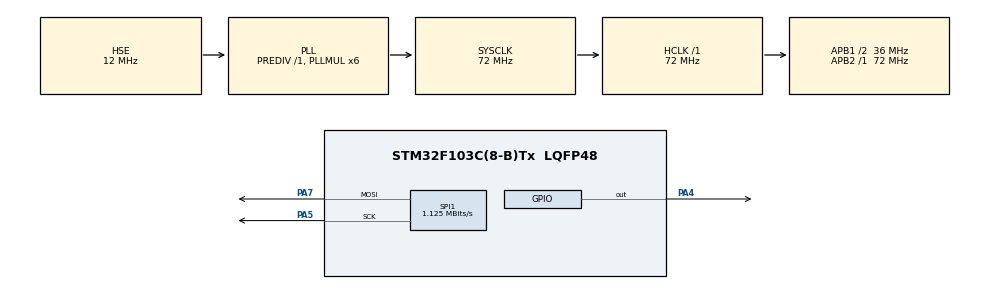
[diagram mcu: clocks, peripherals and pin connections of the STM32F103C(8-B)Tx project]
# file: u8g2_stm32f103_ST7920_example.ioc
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Mcu.Family=STM32F1
RCC.PLLSourceVirtual=RCC_PLLSOURCE_HSE
PA7.Mode=TX_Only_Simplex_Unidirect_Master
PD1-OSC_OUT.Mode=HSE-External-Oscillator
SPI1.VirtualType=VM_MASTER
PD0-OSC_IN.Signal=RCC_OSC_IN
RCC.APB1CLKDivider=RCC_HCLK_DIV2
RCC.SYSCLKSource=RCC_SYSCLKSOURCE_PLLCLK
ProjectManager.StackSize=0x400
PD1-OSC_OUT.Signal=RCC_OSC_OUT
PA13.Signal=SYS_JTMS-SWDIO
ProjectManager.TargetToolchain=STM32CubeIDE
SPI1.Direction=SPI_DIRECTION_2LINES
RCC.HCLKFreq_Value=72000000
RCC.APB2TimFreq_Value=72000000
SPI1.CalculateBaudRate=1.125 MBits/s
RCC.USBFreq_Value=72000000
RCC.AHBFreq_Value=72000000
PD0-OSC_IN.Mode=HSE-External-Oscillator
PA5.Signal=SPI1_SCK
RCC.HSE_VALUE=12000000
board=custom
RCC.PLLMUL=RCC_PLL_MUL6
RCC.APB2Freq_Value=72000000
SPI1.Mode=SPI_MODE_MASTER
PA14.Mode=Serial_Wire
PA13.Mode=Serial_Wire
Mcu.Name=STM32F103C(8-B)Tx
PA4.Signal=GPIO_Output
RCC.SYSCLKFreq_VALUE=72000000
Mcu.Package=LQFP48
PA14.Signal=SYS_JTCK-SWCLK
ProjectManager.HeapSize=0x200
NVIC.PriorityGroup=NVIC_PRIORITYGROUP_4
RCC.APB1TimFreq_Value=72000000
RCC.APB1Freq_Value=36000000
SPI1.BaudRatePrescaler=SPI_BAUDRATEPRESCALER_64
PA5.Mode=TX_Only_Simplex_Unidirect_Master
PA7.Signal=SPI1_MOSI

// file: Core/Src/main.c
/* USER CODE BEGIN Header */
/**
  ******************************************************************************
  * @file           : main.c
  * @brief          : Main program body
  ******************************************************************************
  * @attention
  *
  * <h2><center>&copy; Copyright (c) 2021 STMicroelectronics.
  * All rights reserved.</center></h2>
  *
  * This software component is licensed by ST under BSD 3-Clause license,
  * the "License"; You may not use this file except in compliance with the
  * License. You may obtain a copy of the License at:
  *                        opensource.org/licenses/BSD-3-Clause
  *
  ******************************************************************************
  */
/* USER CODE END Header */
#include "main.h"

/* USER CODE BEGIN Includes */
#include "u8g2.h"
#include "../u8g2/u8g2.h"
/* USER CODE END Includes */

SPI_HandleTypeDef hspi1;

/* USER CODE BEGIN PV */
static u8g2_t u8g2;
/* USER CODE END PV */

void SystemClock_Config(void);
static void MX_GPIO_Init(void);
static void MX_SPI1_Init(void);
/* USER CODE BEGIN PFP */

/* Private variables ---------------------------------------------------------*/

/* USER CODE END PFP */

/* USER CODE BEGIN 0 */
uint8_t u8x8_stm32_gpio_and_delay(U8X8_UNUSED u8x8_t *u8x8,
                                  U8X8_UNUSED uint8_t msg, U8X8_UNUSED uint8_t arg_int,
                                  U8X8_UNUSED void *arg_ptr) {
    switch (msg) {
        case U8X8_MSG_GPIO_AND_DELAY_INIT:
            HAL_Delay(1);
            break;
        case U8X8_MSG_DELAY_MILLI:
            HAL_Delay(arg_int);
            break;
    }
    return 1;
}

uint8_t u8x8_byte_3wire_hw_spi(u8x8_t *u8x8, uint8_t msg, uint8_t arg_int,
                               void *arg_ptr) {
    switch (msg) {
        case U8X8_MSG_BYTE_SEND:
            HAL_SPI_Transmit(&hspi1, (uint8_t *) arg_ptr, arg_int, 10000);
            break;
        case U8X8_MSG_BYTE_START_TRANSFER:
            HAL_GPIO_WritePin(GPIOA, GPIO_PIN_4, !arg_int);
        default:
            return 0;
    }
    return 1;
}
/* USER CODE END 0 */

int main(void)
{

  /* MCU Configuration--------------------------------------------------------*/

  /* Reset of all peripherals, Initializes the Flash interface and the Systick. */
  HAL_Init();

  /* Configure the system clock */
  SystemClock_Config();

  /* Initialize all configured peripherals */
  MX_GPIO_Init();
  MX_SPI1_Init();
  /* USER CODE BEGIN 2 */
    u8g2_Setup_st7920_s_128x64_f(&u8g2, U8G2_R0, u8x8_byte_3wire_hw_spi,
                                 u8x8_stm32_gpio_and_delay);

    u8g2_InitDisplay(&u8g2);
    u8g2_SetPowerSave(&u8g2, 0);
  /* USER CODE END 2 */

  /* Infinite loop */
    while (1) {

    /* USER CODE BEGIN 3 */

        u8g2_ClearBuffer(&u8g2);

        u8g2_SetFontMode(&u8g2, 1);    // Transparent
        u8g2_SetFontDirection(&u8g2, 0);
        u8g2_SetFont(&u8g2, u8g2_font_inb24_mf);
        u8g2_DrawStr(&u8g2, 0, 30, "U");

        u8g2_SetFontDirection(&u8g2, 1);
        u8g2_SetFont(&u8g2, u8g2_font_inb30_mn);
        u8g2_DrawStr(&u8g2, 21, 8, "8");

        u8g2_SetFontDirection(&u8g2, 0);
        u8g2_SetFont(&u8g2, u8g2_font_inb24_mf);
        u8g2_DrawStr(&u8g2, 51, 30, "g");
        u8g2_DrawStr(&u8g2, 67, 30, "\xb2");

        u8g2_DrawHLine(&u8g2, 2, 35, 47);
        u8g2_DrawHLine(&u8g2, 3, 36, 47);
        u8g2_DrawVLine(&u8g2, 45, 32, 12);
        u8g2_DrawVLine(&u8g2, 46, 33, 12);

        u8g2_SetFont(&u8g2, u8g2_font_5x7_tr);
        static int n = 0;
        n++;
        char ch[10];
        itoa(n, ch, 10);
        u8g2_DrawStr(&u8g2, 1, 54, ch);

        u8g2_SendBuffer(&u8g2);
        HAL_Delay(200);
    }
  /* USER CODE END 3 */
}

void SystemClock_Config(void)
{
  RCC_OscInitTypeDef RCC_OscInitStruct = {0};
  RCC_ClkInitTypeDef RCC_ClkInitStruct = {0};

  /** Initializes the RCC Oscillators according to the specified parameters
  * in the RCC_OscInitTypeDef structure.
  */
  RCC_OscInitStruct.OscillatorType = RCC_OSCILLATORTYPE_HSE;
  RCC_OscInitStruct.HSEState = RCC_HSE_ON;
  RCC_OscInitStruct.HSEPredivValue = RCC_HSE_PREDIV_DIV1;
  RCC_OscInitStruct.HSIState = RCC_HSI_ON;
  RCC_OscInitStruct.PLL.PLLState = RCC_PLL_ON;
  RCC_OscInitStruct.PLL.PLLSource = RCC_PLLSOURCE_HSE;
  RCC_OscInitStruct.PLL.PLLMUL = RCC_PLL_MUL6;
  if (HAL_RCC_OscConfig(&RCC_OscInitStruct) != HAL_OK)
  {
    Error_Handler();
  }
  /** Initializes the CPU, AHB and APB buses clocks
  */
  RCC_ClkInitStruct.ClockType = RCC_CLOCKTYPE_HCLK|RCC_CLOCKTYPE_SYSCLK
                              |RCC_CLOCKTYPE_PCLK1|RCC_CLOCKTYPE_PCLK2;
  RCC_ClkInitStruct.SYSCLKSource = RCC_SYSCLKSOURCE_PLLCLK;
  RCC_ClkInitStruct.AHBCLKDivider = RCC_SYSCLK_DIV1;
  RCC_ClkInitStruct.APB1CLKDivider = RCC_HCLK_DIV2;
  RCC_ClkInitStruct.APB2CLKDivider = RCC_HCLK_DIV1;

  if (HAL_RCC_ClockConfig(&RCC_ClkInitStruct, FLASH_LATENCY_2) != HAL_OK)
  {
    Error_Handler();
  }
}

static void MX_SPI1_Init(void)
{

  /* SPI1 parameter configuration*/
  hspi1.Instance = SPI1;
  hspi1.Init.Mode = SPI_MODE_MASTER;
  hspi1.Init.Direction = SPI_DIRECTION_2LINES;
  hspi1.Init.DataSize = SPI_DATASIZE_8BIT;
  hspi1.Init.CLKPolarity = SPI_POLARITY_LOW;
  hspi1.Init.CLKPhase = SPI_PHASE_1EDGE;
  hspi1.Init.NSS = SPI_NSS_SOFT;
  hspi1.Init.BaudRatePrescaler = SPI_BAUDRATEPRESCALER_64;
  hspi1.Init.FirstBit = SPI_FIRSTBIT_MSB;
  hspi1.Init.TIMode = SPI_TIMODE_DISABLE;
  hspi1.Init.CRCCalculation = SPI_CRCCALCULATION_DISABLE;
  hspi1.Init.CRCPolynomial = 10;
  if (HAL_SPI_Init(&hspi1) != HAL_OK)
  {
    Error_Handler();
  }

}

static void MX_GPIO_Init(void)
{
  GPIO_InitTypeDef GPIO_InitStruct = {0};

  /* GPIO Ports Clock Enable */
  __HAL_RCC_GPIOD_CLK_ENABLE();
  __HAL_RCC_GPIOA_CLK_ENABLE();

  /*Configure GPIO pin Output Level */
  HAL_GPIO_WritePin(GPIOA, GPIO_PIN_4, GPIO_PIN_RESET);

  /*Configure GPIO pin : PA4 */
  GPIO_InitStruct.Pin = GPIO_PIN_4;
  GPIO_InitStruct.Mode = GPIO_MODE_OUTPUT_PP;
  GPIO_InitStruct.Pull = GPIO_NOPULL;
  GPIO_InitStruct.Speed = GPIO_SPEED_FREQ_LOW;
  HAL_GPIO_Init(GPIOA, &GPIO_InitStruct);

}

void Error_Handler(void)
{
    __disable_irq();
    while (1) {
    }
}

/************************ (C) COPYRIGHT STMicroelectronics *****END OF FILE****/
